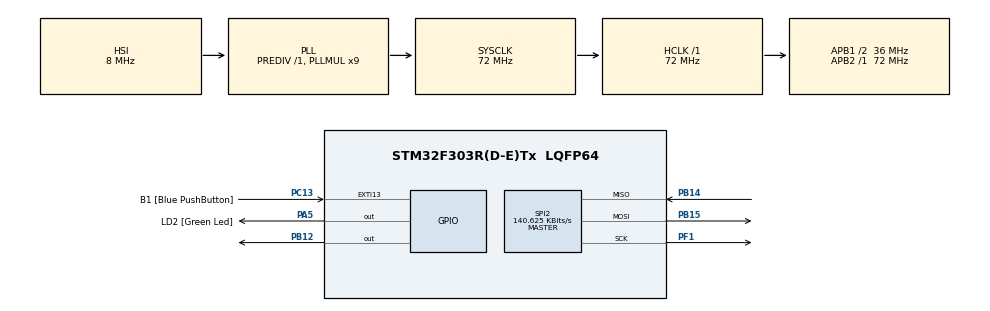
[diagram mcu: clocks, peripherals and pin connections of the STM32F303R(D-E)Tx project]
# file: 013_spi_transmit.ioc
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Mcu.Family=STM32F3
PC15-OSC32_OUT.Mode=LSE-External-Oscillator
RCC.CortexFreq_Value=72000000
SPI2.VirtualType=VM_MASTER
PC13.Signal=GPXTI13
PA14.GPIO_Label=TCK
RCC.SYSCLKSourceVirtual=RCC_SYSCLKSOURCE_PLLCLK
PC13.GPIO_Label=B1 [Blue PushButton]
RCC.APB1CLKDivider=RCC_HCLK_DIV2
PC14-OSC32_IN.Signal=RCC_OSC32_IN
PB15.Signal=SPI2_MOSI
ProjectManager.StackSize=0x400
PA13.Signal=SYS_JTMS-SWDIO
SPI2.CLKPolarity=SPI_POLARITY_LOW
ProjectManager.TargetToolchain=STM32CubeIDE
RCC.HCLKFreq_Value=72000000
RCC.APB2TimFreq_Value=72000000
PB12.PinState=GPIO_PIN_SET
RCC.USBFreq_Value=72000000
PC15-OSC32_OUT.Signal=RCC_OSC32_OUT
RCC.AHBFreq_Value=72000000
SPI2.BaudRatePrescaler=SPI_BAUDRATEPRESCALER_256
PB12.GPIO_Speed=GPIO_SPEED_FREQ_HIGH
PF0-OSC_IN.Mode=HSE-External-Clock-Source
PB14.Signal=SPI2_MISO
PA5.Signal=GPIO_Output
RCC.HSE_VALUE=8000000
board=NUCLEO-F303RE
RCC.RCC_PLLsource_Clock_Source_FROM_HSE=RCC_HSE_PREDIV_DIV2
RCC.PLLMUL=RCC_PLL_MUL9
PB15.Mode=Full_Duplex_Master
RCC.APB2Freq_Value=72000000
PC14-OSC32_IN.Mode=LSE-External-Oscillator
PA14.Mode=Serial_Wire
PB14.Mode=Full_Duplex_Master
PA5.GPIO_PuPd=GPIO_NOPULL
SPI2.CalculateBaudRate=140.625 KBits/s
PA13.Mode=Serial_Wire
Mcu.Name=STM32F303R(D-E)Tx
PA13.GPIO_Label=TMS
RCC.SYSCLKFreq_VALUE=72000000
Mcu.Package=LQFP64
SPI2.Mode=SPI_MODE_MASTER
PA5.GPIO_Label=LD2 [Green Led]
PC13.GPIO_ModeDefaultEXTI=GPIO_MODE_IT_FALLING
PA14.Signal=SYS_JTCK-SWCLK
ProjectManager.HeapSize=0x200
SPI2.CLKPhase=SPI_PHASE_1EDGE
RCC.HSI_VALUE=8000000
RCC.PLLP=RCC_PLLP_DIV4
PA5.GPIO_Speed=GPIO_SPEED_FREQ_LOW
RCC.PLLQ=7
NVIC.PriorityGroup=NVIC_PRIORITYGROUP_0
RCC.PLLM=8
RCC.PLLN=336
RCC.APB1TimFreq_Value=72000000
SPI2.DataSize=SPI_DATASIZE_8BIT
SPI2.Direction=SPI_DIRECTION_2LINES
PF0-OSC_IN.Signal=RCC_OSC_IN
PF1-OSC_OUT.Mode=Full_Duplex_Master
RCC.APB1Freq_Value=36000000
PA5.GPIO_Mode=GPIO_MODE_OUTPUT_PP
PB12.Signal=GPIO_Output
PF1-OSC_OUT.Signal=SPI2_SCK

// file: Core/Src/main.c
/* USER CODE BEGIN Header */
/**
  ******************************************************************************
  * @file           : main.c
  * @brief          : Main program body
  ******************************************************************************
  * @attention
  *
  * <h2><center>&copy; Copyright (c) 2021 STMicroelectronics.
  * All rights reserved.</center></h2>
  *
  * This software component is licensed by ST under BSD 3-Clause license,
  * the "License"; You may not use this file except in compliance with the
  * License. You may obtain a copy of the License at:
  *                        opensource.org/licenses/BSD-3-Clause
  *
  ******************************************************************************
  */
/* USER CODE END Header */
#include "main.h"

SPI_HandleTypeDef hspi2;

/* USER CODE BEGIN PV */
uint8_t data[]="deneme";

/* USER CODE END PV */

void SystemClock_Config(void);
static void MX_GPIO_Init(void);
static void MX_SPI2_Init(void);
/* USER CODE BEGIN PFP */
void spi_write (uint8_t* value);
/* USER CODE END PFP */

int main(void)
{

  /* MCU Configuration--------------------------------------------------------*/

  /* Reset of all peripherals, Initializes the Flash interface and the Systick. */
  HAL_Init();

  /* Configure the system clock */
  SystemClock_Config();

  /* Initialize all configured peripherals */
  MX_GPIO_Init();
  MX_SPI2_Init();

  /* Infinite loop */
  while (1)
  {

    /* USER CODE BEGIN 3 */
		HAL_GPIO_WritePin(GPIOB,GPIO_PIN_12,GPIO_PIN_RESET);
		HAL_SPI_Transmit (&hspi2,(uint8_t*)data,sizeof(data), 1000);  // write data to register
		HAL_GPIO_WritePin(GPIOB,GPIO_PIN_12,GPIO_PIN_SET);
	  HAL_Delay(100);
  }
  /* USER CODE END 3 */
}

void SystemClock_Config(void)
{
  RCC_OscInitTypeDef RCC_OscInitStruct = {0};
  RCC_ClkInitTypeDef RCC_ClkInitStruct = {0};

  /** Initializes the RCC Oscillators according to the specified parameters
  * in the RCC_OscInitTypeDef structure.
  */
  RCC_OscInitStruct.OscillatorType = RCC_OSCILLATORTYPE_HSI;
  RCC_OscInitStruct.HSIState = RCC_HSI_ON;
  RCC_OscInitStruct.HSICalibrationValue = RCC_HSICALIBRATION_DEFAULT;
  RCC_OscInitStruct.PLL.PLLState = RCC_PLL_ON;
  RCC_OscInitStruct.PLL.PLLSource = RCC_PLLSOURCE_HSI;
  RCC_OscInitStruct.PLL.PLLMUL = RCC_PLL_MUL9;
  RCC_OscInitStruct.PLL.PREDIV = RCC_PREDIV_DIV1;
  if (HAL_RCC_OscConfig(&RCC_OscInitStruct) != HAL_OK)
  {
    Error_Handler();
  }
  /** Initializes the CPU, AHB and APB buses clocks
  */
  RCC_ClkInitStruct.ClockType = RCC_CLOCKTYPE_HCLK|RCC_CLOCKTYPE_SYSCLK
                              |RCC_CLOCKTYPE_PCLK1|RCC_CLOCKTYPE_PCLK2;
  RCC_ClkInitStruct.SYSCLKSource = RCC_SYSCLKSOURCE_PLLCLK;
  RCC_ClkInitStruct.AHBCLKDivider = RCC_SYSCLK_DIV1;
  RCC_ClkInitStruct.APB1CLKDivider = RCC_HCLK_DIV2;
  RCC_ClkInitStruct.APB2CLKDivider = RCC_HCLK_DIV1;

  if (HAL_RCC_ClockConfig(&RCC_ClkInitStruct, FLASH_LATENCY_2) != HAL_OK)
  {
    Error_Handler();
  }
}

static void MX_SPI2_Init(void)
{

  /* SPI2 parameter configuration*/
  hspi2.Instance = SPI2;
  hspi2.Init.Mode = SPI_MODE_MASTER;
  hspi2.Init.Direction = SPI_DIRECTION_2LINES;
  hspi2.Init.DataSize = SPI_DATASIZE_8BIT;
  hspi2.Init.CLKPolarity = SPI_POLARITY_LOW;
  hspi2.Init.CLKPhase = SPI_PHASE_1EDGE;
  hspi2.Init.NSS = SPI_NSS_SOFT;
  hspi2.Init.BaudRatePrescaler = SPI_BAUDRATEPRESCALER_256;
  hspi2.Init.FirstBit = SPI_FIRSTBIT_MSB;
  hspi2.Init.TIMode = SPI_TIMODE_DISABLE;
  hspi2.Init.CRCCalculation = SPI_CRCCALCULATION_DISABLE;
  hspi2.Init.CRCPolynomial = 7;
  hspi2.Init.CRCLength = SPI_CRC_LENGTH_DATASIZE;
  hspi2.Init.NSSPMode = SPI_NSS_PULSE_ENABLE;
  if (HAL_SPI_Init(&hspi2) != HAL_OK)
  {
    Error_Handler();
  }

}

static void MX_GPIO_Init(void)
{
  GPIO_InitTypeDef GPIO_InitStruct = {0};

  /* GPIO Ports Clock Enable */
  __HAL_RCC_GPIOC_CLK_ENABLE();
  __HAL_RCC_GPIOF_CLK_ENABLE();
  __HAL_RCC_GPIOA_CLK_ENABLE();
  __HAL_RCC_GPIOB_CLK_ENABLE();

  /*Configure GPIO pin Output Level */
  HAL_GPIO_WritePin(LD2_GPIO_Port, LD2_Pin, GPIO_PIN_RESET);

  /*Configure GPIO pin Output Level */
  HAL_GPIO_WritePin(GPIOB, GPIO_PIN_12, GPIO_PIN_SET);

  /*Configure GPIO pin : B1_Pin */
  GPIO_InitStruct.Pin = B1_Pin;
  GPIO_InitStruct.Mode = GPIO_MODE_IT_FALLING;
  GPIO_InitStruct.Pull = GPIO_NOPULL;
  HAL_GPIO_Init(B1_GPIO_Port, &GPIO_InitStruct);

  /*Configure GPIO pin : LD2_Pin */
  GPIO_InitStruct.Pin = LD2_Pin;
  GPIO_InitStruct.Mode = GPIO_MODE_OUTPUT_PP;
  GPIO_InitStruct.Pull = GPIO_NOPULL;
  GPIO_InitStruct.Speed = GPIO_SPEED_FREQ_LOW;
  HAL_GPIO_Init(LD2_GPIO_Port, &GPIO_InitStruct);

  /*Configure GPIO pin : PB12 */
  GPIO_InitStruct.Pin = GPIO_PIN_12;
  GPIO_InitStruct.Mode = GPIO_MODE_OUTPUT_PP;
  GPIO_InitStruct.Pull = GPIO_NOPULL;
  GPIO_InitStruct.Speed = GPIO_SPEED_FREQ_HIGH;
  HAL_GPIO_Init(GPIOB, &GPIO_InitStruct);

}

/* USER CODE BEGIN 4 */
void spi_write (uint8_t* value)
{

}
/* USER CODE END 4 */

void Error_Handler(void)
{
  __disable_irq();
  while (1)
  {
  }
}

/************************ (C) COPYRIGHT STMicroelectronics *****END OF FILE****/
